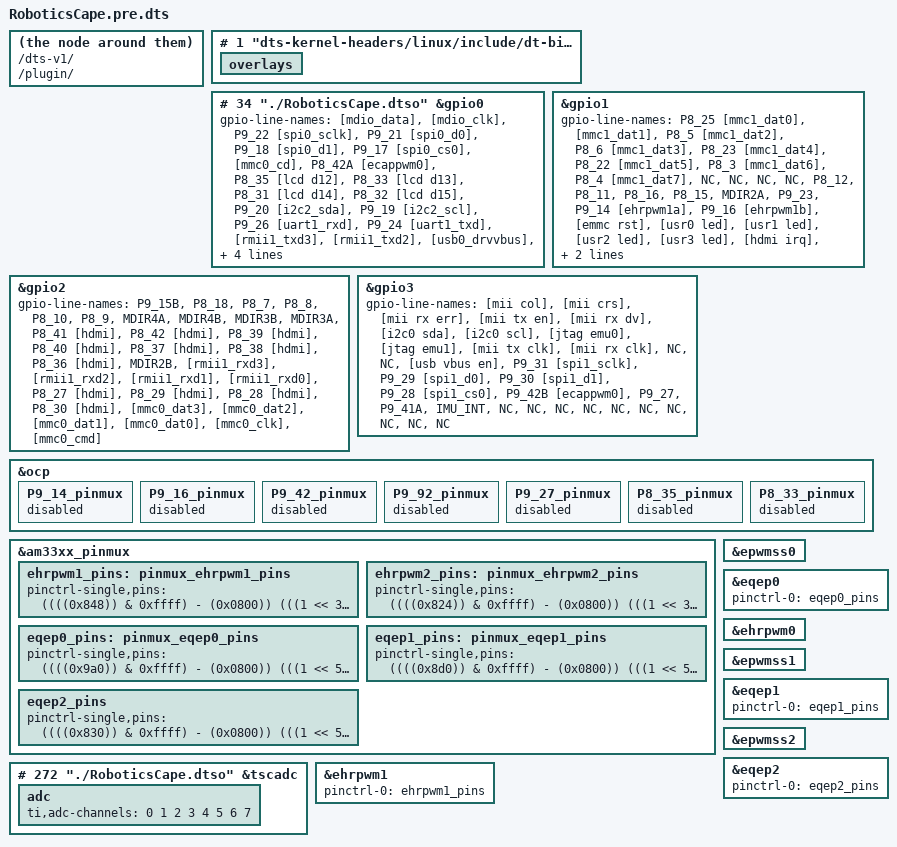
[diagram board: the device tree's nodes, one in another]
# 0 "./RoboticsCape.dtso"
# 0 "<built-in>"
# 0 "<command-line>"
# 1 "./RoboticsCape.dtso"
/dts-v1/;
/plugin/;

# 1 "dts-kernel-headers/linux/include/dt-bindings/pinctrl/am33xx.h" 1
# 9 "dts-kernel-headers/linux/include/dt-bindings/pinctrl/am33xx.h"
# 1 "dts-kernel-headers/linux/include/dt-bindings/pinctrl/omap.h" 1
# 10 "dts-kernel-headers/linux/include/dt-bindings/pinctrl/am33xx.h" 2
# 5 "./RoboticsCape.dtso" 2
# 1 "dts-kernel-headers/linux/include/dt-bindings/gpio/gpio.h" 1
# 6 "./RoboticsCape.dtso" 2
# 1 "dts-kernel-headers/linux/include/dt-bindings/interrupt-controller/irq.h" 1
# 7 "./RoboticsCape.dtso" 2

&{/chosen} {
    overlays {};
};
# 34 "./RoboticsCape.dtso"
&gpio0 {
 gpio-line-names =
  "[mdio_data]",
  "[mdio_clk]",
  "P9_22 [spi0_sclk]",
  "P9_21 [spi0_d0]",
  "P9_18 [spi0_d1]",
  "P9_17 [spi0_cs0]",
  "[mmc0_cd]",
  "P8_42A [ecappwm0]",
  "P8_35 [lcd d12]",
  "P8_33 [lcd d13]",
  "P8_31 [lcd d14]",
  "P8_32 [lcd d15]",
  "P9_20 [i2c2_sda]",
  "P9_19 [i2c2_scl]",
  "P9_26 [uart1_rxd]",
  "P9_24 [uart1_txd]",
  "[rmii1_txd3]",
  "[rmii1_txd2]",
  "[usb0_drvvbus]",
  "[hdmi cec]",
  "MOT_STBY",
  "[rmii1_txd1]",
  "P8_19 [ehrpwm2a]",
  "P8_13 [ehrpwm2b]",
  "NC",
  "NC",
  "P8_14",
  "P8_17",
  "[rmii1_txd0]",
  "[rmii1_refclk]",
  "P9_11 [uart4_rxd]",
  "MDIR1B";
};

&gpio1 {
 gpio-line-names =
  "P8_25 [mmc1_dat0]",
  "[mmc1_dat1]",
  "P8_5 [mmc1_dat2]",
  "P8_6 [mmc1_dat3]",
  "P8_23 [mmc1_dat4]",
  "P8_22 [mmc1_dat5]",
  "P8_3 [mmc1_dat6]",
  "P8_4 [mmc1_dat7]",
  "NC",
  "NC",
  "NC",
  "NC",
  "P8_12",
  "P8_11",
  "P8_16",
  "P8_15",
  "MDIR2A",
  "P9_23",
  "P9_14 [ehrpwm1a]",
  "P9_16 [ehrpwm1b]",
  "[emmc rst]",
  "[usr0 led]",
  "[usr1 led]",
  "[usr2 led]",
  "[usr3 led]",
  "[hdmi irq]",
  "[usb vbus oc]",
  "[hdmi audio]",
  "MDIR1A",
  "P8_26",
  "P8_21 [emmc]",
  "P8_20 [emmc]";
};

&gpio2 {
 gpio-line-names =
  "P9_15B",
  "P8_18",
  "P8_7",
  "P8_8",
  "P8_10",
  "P8_9",
  "MDIR4A",
  "MDIR4B",
  "MDIR3B",
  "MDIR3A",
  "P8_41 [hdmi]",
  "P8_42 [hdmi]",
  "P8_39 [hdmi]",
  "P8_40 [hdmi]",
  "P8_37 [hdmi]",
  "P8_38 [hdmi]",
  "P8_36 [hdmi]",
  "MDIR2B",
  "[rmii1_rxd3]",
  "[rmii1_rxd2]",
  "[rmii1_rxd1]",
  "[rmii1_rxd0]",
  "P8_27 [hdmi]",
  "P8_29 [hdmi]",
  "P8_28 [hdmi]",
  "P8_30 [hdmi]",
  "[mmc0_dat3]",
  "[mmc0_dat2]",
  "[mmc0_dat1]",
  "[mmc0_dat0]",
  "[mmc0_clk]",
  "[mmc0_cmd]";
};

&gpio3 {
 gpio-line-names =
  "[mii col]",
  "[mii crs]",
  "[mii rx err]",
  "[mii tx en]",
  "[mii rx dv]",
  "[i2c0 sda]",
  "[i2c0 scl]",
  "[jtag emu0]",
  "[jtag emu1]",
  "[mii tx clk]",
  "[mii rx clk]",
  "NC",
  "NC",
  "[usb vbus en]",
  "P9_31 [spi1_sclk]",
  "P9_29 [spi1_d0]",
  "P9_30 [spi1_d1]",
  "P9_28 [spi1_cs0]",
  "P9_42B [ecappwm0]",
  "P9_27",
  "P9_41A",
  "IMU_INT",
  "NC",
  "NC",
  "NC",
  "NC",
  "NC",
  "NC",
  "NC",
  "NC",
  "NC",
  "NC";
};





&ocp {




 P9_14_pinmux { status = "disabled"; };
 P9_16_pinmux { status = "disabled"; };


 P9_42_pinmux { status = "disabled"; };
 P9_92_pinmux { status = "disabled"; };
 P9_27_pinmux { status = "disabled"; };


 P8_35_pinmux { status = "disabled"; };
 P8_33_pinmux { status = "disabled"; };
};


&am33xx_pinmux {
 ehrpwm1_pins: pinmux_ehrpwm1_pins {
  pinctrl-single,pins = <
   ((((0x848)) & 0xffff) - (0x0800)) (((1 << 3))) (6)
   ((((0x84c)) & 0xffff) - (0x0800)) (((1 << 3))) (6)
  >;
 };

 ehrpwm2_pins: pinmux_ehrpwm2_pins {
  pinctrl-single,pins = <
   ((((0x824)) & 0xffff) - (0x0800)) (((1 << 3))) (4)
   ((((0x820)) & 0xffff) - (0x0800)) (((1 << 3))) (4)
  >;
 };




 eqep0_pins: pinmux_eqep0_pins {
  pinctrl-single,pins = <
   ((((0x9a0)) & 0xffff) - (0x0800)) (((1 << 5))) (1)
   ((((0x9a4)) & 0xffff) - (0x0800)) (((1 << 5))) (1)
  >;
 };





 eqep1_pins: pinmux_eqep1_pins {
  pinctrl-single,pins = <
   ((((0x8d0)) & 0xffff) - (0x0800)) (((1 << 5) | (1 << 3))) (2)
   ((((0x8d4)) & 0xffff) - (0x0800)) (((1 << 5) | (1 << 3))) (2)
  >;
 };


 eqep2_pins: eqep2_pins {
  pinctrl-single,pins = <
   ((((0x830)) & 0xffff) - (0x0800)) (((1 << 5) | (1 << 3))) (4)
   ((((0x834)) & 0xffff) - (0x0800)) (((1 << 5) | (1 << 3))) (4)
  >;
 };


};
# 272 "./RoboticsCape.dtso"
&tscadc {
 status = "okay";
 adc {
  ti,adc-channels = <0 1 2 3 4 5 6 7>;
 };
};







&epwmss0 {
 status = "okay";
};

&eqep0 {
 pinctrl-names = "default";
 pinctrl-0 = <&eqep0_pins>;
 status = "okay";
};

&ehrpwm0 {
 status = "okay";
};






&epwmss1 {
 status = "okay";
};

&eqep1 {
 pinctrl-names = "default";
 pinctrl-0 = <&eqep1_pins>;
 status = "okay";
};

&ehrpwm1 {
 pinctrl-names = "default";
 pinctrl-0 = <&ehrpwm1_pins>;
 status = "okay";
};

&epwmss2 {
 status = "okay";
};

&eqep2 {
 pinctrl-names = "default";
 pinctrl-0 = <&eqep2_pins>;
 status = "okay";
};
